# SWM221 register map
File version: 1.0
CPU: CM0 r1p0, little endian, 2 interrupt priority bits
Registers are 32-bit, read-write, no defined reset value unless marked. A register's access mark holds for its fields unless they carry their own. Offsets are from the block's base; [hi:lo] are bit positions; lines under a group give offsets from that group; {n}, {i} and the like mark numbered series; 'fields as' and 'values as' point back to an identical list.

## I2C0 — Registers group
Base 0x40042000
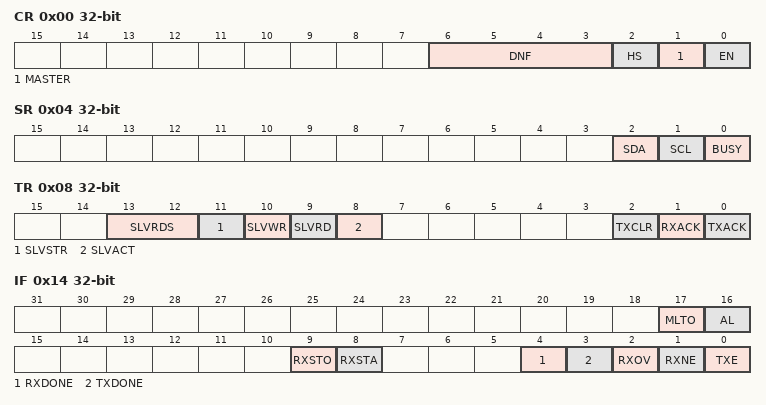
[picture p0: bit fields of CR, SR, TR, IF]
0x00 CR
  [6:3] DNF, [2] HS, [1] MASTER, [0] EN
0x04 SR
  [2] SDA, [1] SCL, [0] BUSY
0x08 TR
  [13:12] SLVRDS, [11] SLVSTR, [10] SLVWR, [9] SLVRD, [8] SLVACT, [2] TXCLR, [1] RXACK, [0] TXACK
0x0C RXDATA
0x10 TXDATA
0x14 IF
  [17] MLTO, [16] AL, [9] RXSTO, [8] RXSTA, [4] RXDONE, [3] TXDONE, [2] RXOV, [1] RXNE, [0] TXE
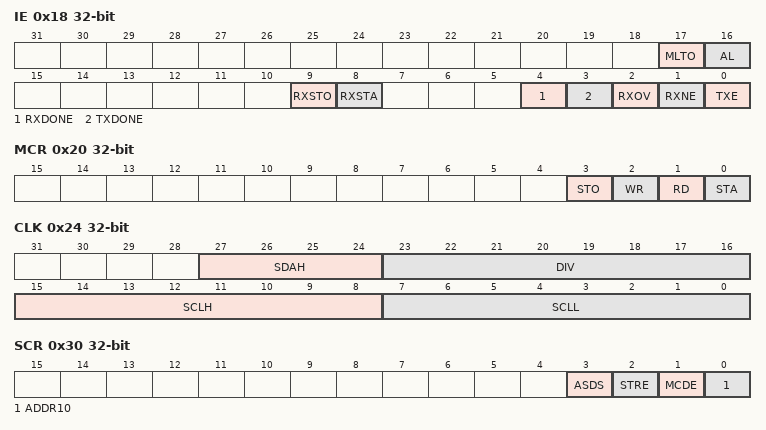
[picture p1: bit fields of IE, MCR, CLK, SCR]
0x18 IE
  fields as IF
0x20 MCR
  [3] STO, [2] WR, [1] RD, [0] STA
0x24 CLK
  [27:24] SDAH, [23:16] DIV, [15:8] SCLH, [7:0] SCLL
0x30 SCR
  [3] ASDS, [2] STRE, [1] MCDE, [0] ADDR10
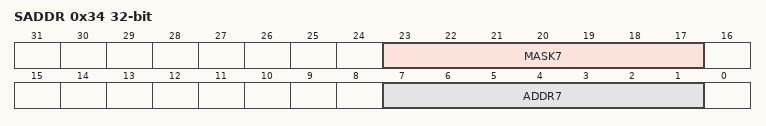
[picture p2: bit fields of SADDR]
0x34 SADDR
  [23:17] MASK7, [7:1] ADDR7

## CAN0 — Registers group
Base 0x40042800
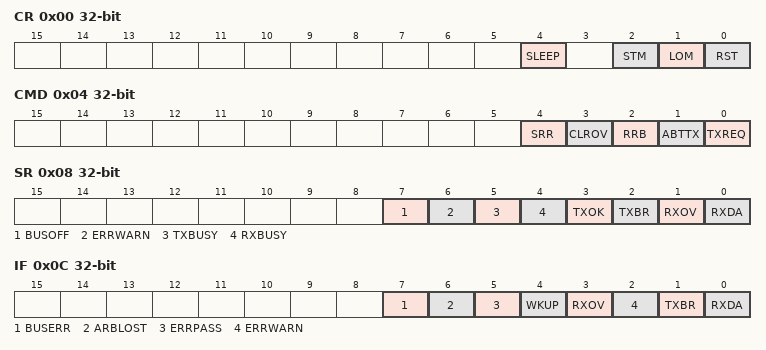
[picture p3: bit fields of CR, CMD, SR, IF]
0x00 CR
  [4] SLEEP, [2] STM, [1] LOM, [0] RST
0x04 CMD wo
  [4] SRR, [3] CLROV, [2] RRB, [1] ABTTX, [0] TXREQ
0x08 SR ro
  [7] BUSOFF, [6] ERRWARN, [5] TXBUSY, [4] RXBUSY, [3] TXOK, [2] TXBR, [1] RXOV, [0] RXDA
0x0C IF
  [7] BUSERR, [6] ARBLOST, [5] ERRPASS, [4] WKUP, [3] RXOV, [2] ERRWARN, [1] TXBR, [0] RXDA
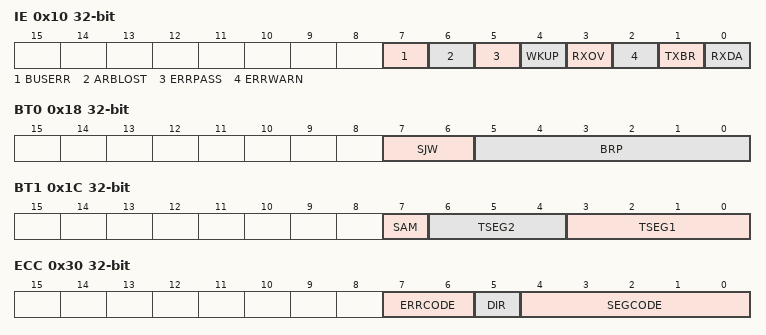
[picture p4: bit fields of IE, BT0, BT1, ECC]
0x10 IE
  fields as IF
0x14 BT2
  [3:0] BRP
0x18 BT0
  [7:6] SJW, [5:0] BRP
0x1C BT1
  [7] SAM, [6:4] TSEG2, [3:0] TSEG1
0x24 AFM
0x28 AFE
0x2C ALC ro
0x30 ECC ro
  [7:6] ERRCODE, [5] DIR, [4:0] SEGCODE
0x34 EWLIM
0x38 RXERR
0x3C TXERR
0x40 FRAME group — register cluster
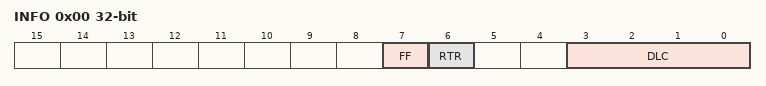
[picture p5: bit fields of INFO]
  0x00 INFO
    [7] FF, [6] RTR, [3:0] DLC
  {0x4+4j} DATA[{j}] (j=0..11)
0x74 RMCNT ro
{0x300+4i} ACR[{i}] (i=0..15)
{0x380+4i} AMR[{i}] (i=0..15)

## ADC0 — Registers group
Base 0x40044800
Same registers: ADC1 0x40044900
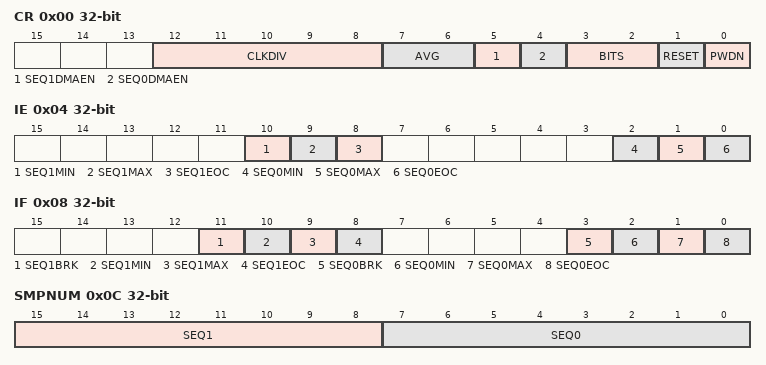
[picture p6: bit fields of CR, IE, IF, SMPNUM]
0x00 CR
  [12:8] CLKDIV, [7:6] AVG, [5] SEQ1DMAEN, [4] SEQ0DMAEN, [3:2] BITS, [1] RESET, [0] PWDN
0x04 IE
  [10] SEQ1MIN, [9] SEQ1MAX, [8] SEQ1EOC, [2] SEQ0MIN, [1] SEQ0MAX, [0] SEQ0EOC
0x08 IF
  [11] SEQ1BRK, [10] SEQ1MIN, [9] SEQ1MAX, [8] SEQ1EOC, [3] SEQ0BRK, [2] SEQ0MIN, [1] SEQ0MAX, [0] SEQ0EOC
0x0C SMPNUM
  [15:8] SEQ1, [7:0] SEQ0
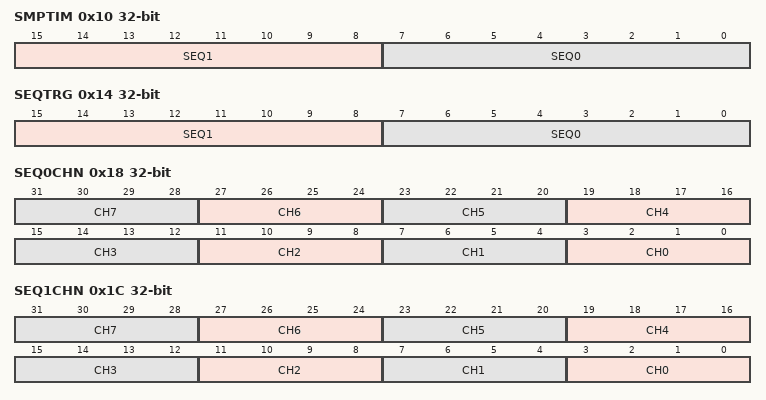
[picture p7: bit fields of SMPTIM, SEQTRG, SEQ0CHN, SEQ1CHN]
0x10 SMPTIM
  [15:8] SEQ1, [7:0] SEQ0
0x14 SEQTRG
  [15:8] SEQ1, [7:0] SEQ0
0x18 SEQ0CHN
  [4n+3:4n] CH{n} (n=0..7)
0x1C SEQ1CHN
  [4n+3:4n] CH{n} (n=0..7)
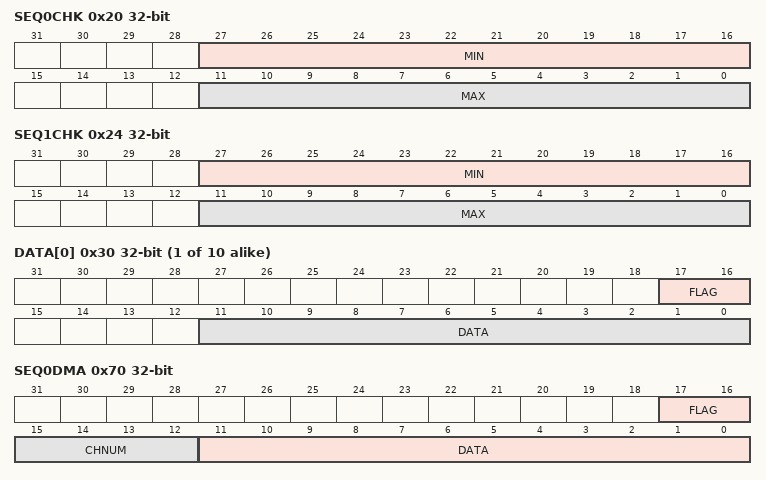
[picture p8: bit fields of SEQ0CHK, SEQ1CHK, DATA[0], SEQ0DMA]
0x20 SEQ0CHK
  [27:16] MIN, [11:0] MAX
0x24 SEQ1CHK
  [27:16] MIN, [11:0] MAX
{0x30+4i} DATA[{i}] (i=0..9)
  [17:16] FLAG, [11:0] DATA
0x70 SEQ0DMA
  [17:16] FLAG, [15:12] CHNUM, [11:0] DATA
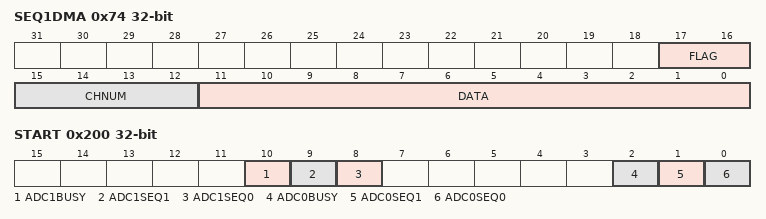
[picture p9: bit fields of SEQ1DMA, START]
0x74 SEQ1DMA
  [17:16] FLAG, [15:12] CHNUM, [11:0] DATA
0x200 START
  [10] ADC1BUSY, [9] ADC1SEQ1, [8] ADC1SEQ0, [2] ADC0BUSY, [1] ADC0SEQ1, [0] ADC0SEQ0

## PWM0 — Registers group
Base 0x40043000
Same registers: PWM1 0x40043080
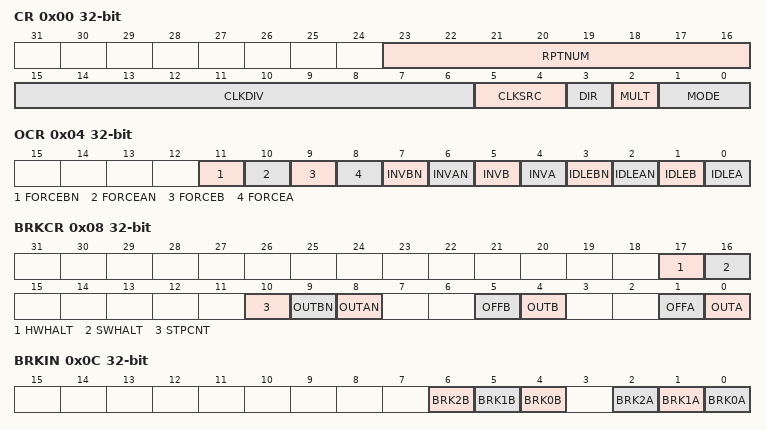
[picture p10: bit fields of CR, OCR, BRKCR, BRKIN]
0x00 CR
  [23:16] RPTNUM, [15:6] CLKDIV, [5:4] CLKSRC, [3] DIR, [2] MULT, [1:0] MODE
0x04 OCR
  [11] FORCEBN, [10] FORCEAN, [9] FORCEB, [8] FORCEA, [7] INVBN, [6] INVAN, [5] INVB, [4] INVA, [3] IDLEBN, [2] IDLEAN, [1] IDLEB, [0] IDLEA
0x08 BRKCR
  [17] HWHALT, [16] SWHALT, [10] STPCNT, [9] OUTBN, [8] OUTAN, [5] OFFB, [4] OUTB, [1] OFFA, [0] OUTA
0x0C BRKIN
  [6] BRK2B, [5] BRK1B, [4] BRK0B, [2] BRK2A, [1] BRK1A, [0] BRK0A
0x20 PERIOD
0x24 CMPA
0x28 CMPB
0x2C DZA
0x30 DZB
0x34 CMPA2
0x38 CMPB2
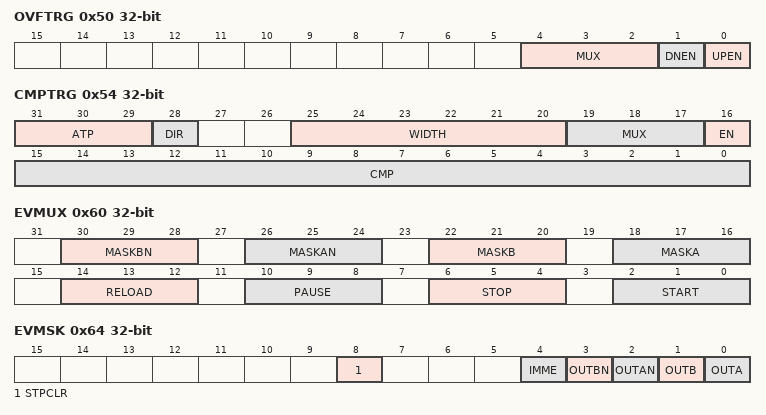
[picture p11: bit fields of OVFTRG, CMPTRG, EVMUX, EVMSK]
0x50 OVFTRG
  [4:2] MUX, [1] DNEN, [0] UPEN
0x54 CMPTRG
  [31:29] ATP, [28] DIR, [25:20] WIDTH, [19:17] MUX, [16] EN, [15:0] CMP
0x58 CMPTRG2
  [2:0] INTV
0x60 EVMUX
  [30:28] MASKBN, [26:24] MASKAN, [22:20] MASKB, [18:16] MASKA, [14:12] RELOAD, [10:8] PAUSE, [6:4] STOP, [2:0] START
0x64 EVMSK
  [8] STPCLR, [4] IMME, [3] OUTBN, [2] OUTAN, [1] OUTB, [0] OUTA
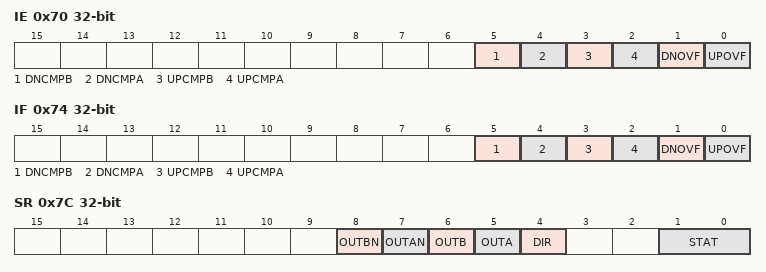
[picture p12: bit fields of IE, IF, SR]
0x70 IE
  [5] DNCMPB, [4] DNCMPA, [3] UPCMPB, [2] UPCMPA, [1] DNOVF, [0] UPOVF
0x74 IF
  [5] DNCMPB, [4] DNCMPA, [3] UPCMPB, [2] UPCMPA, [1] DNOVF, [0] UPOVF
0x78 VALUE
0x7C SR
  [8] OUTBN, [7] OUTAN, [6] OUTB, [5] OUTA, [4] DIR, [1:0] STAT

## PWMG — Registers group
Base 0x40043400
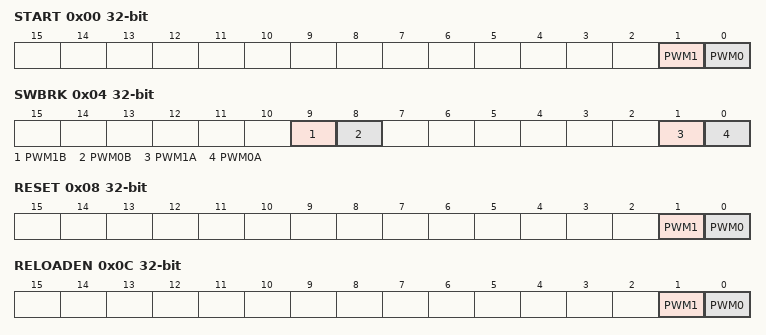
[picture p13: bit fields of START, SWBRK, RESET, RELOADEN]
0x00 START
  [1] PWM1, [0] PWM0
0x04 SWBRK
  [9] PWM1B, [8] PWM0B, [1] PWM1A, [0] PWM0A
0x08 RESET
  [1] PWM1, [0] PWM0
0x0C RELOADEN
  [1] PWM1, [0] PWM0
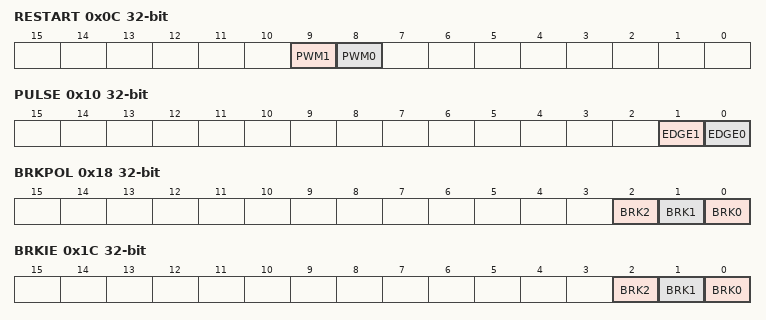
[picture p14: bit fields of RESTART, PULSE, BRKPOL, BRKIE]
0x0C RESTART (alternate view of RELOADEN)
  [9] PWM1, [8] PWM0
0x10 PULSE
  [1] EDGE1, [0] EDGE0
0x14 FILTER
0x18 BRKPOL
  [2] BRK2, [1] BRK1, [0] BRK0
0x1C BRKIE
  [2] BRK2, [1] BRK1, [0] BRK0
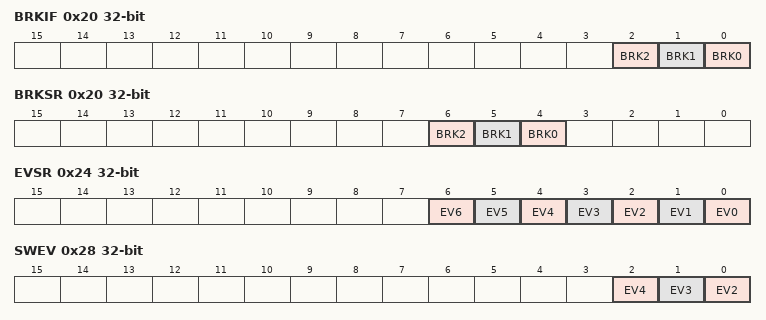
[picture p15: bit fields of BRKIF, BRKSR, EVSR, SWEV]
0x20 BRKIF
  [2] BRK2, [1] BRK1, [0] BRK0
0x20 BRKSR (alternate view of BRKIF)
  [6] BRK2, [5] BRK1, [4] BRK0
0x24 EVSR
  [n] EV{n} (n=0..6)
0x28 SWEV
  [2] EV4, [1] EV3, [0] EV2

## DIV — Registers group
Base 0x40003000
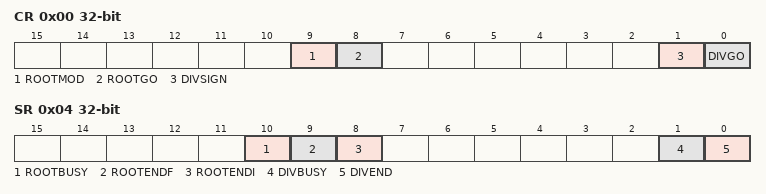
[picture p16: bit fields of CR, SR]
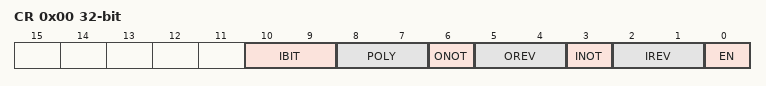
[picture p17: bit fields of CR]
0x00 CR
  [9] ROOTMOD, [8] ROOTGO, [1] DIVSIGN, [0] DIVGO
0x04 SR
  [10] ROOTBUSY, [9] ROOTENDF, [8] ROOTENDI, [1] DIVBUSY, [0] DIVEND
0x08 IE
0x10 DIVIDEND
0x14 DIVISOR
0x18 QUO
0x1C REMAIN
0x20 RADICAND
0x24 ROOT

## CRC — Registers group
Base 0x40002800
0x00 CR
  [10:9] IBIT, [8:7] POLY, [6] ONOT, [5:4] OREV, [3] INOT, [2:1] IREV, [0] EN
0x04 DATAIN wo
0x08 INIVAL
0x0C RESULT ro

## DMA — Registers group
Base 0x40000800
0x00 IF
  [7] ERR1, [6] HALF1, [5] DONE1, [4] GLB1, [3] ERR0, [2] HALF0, [1] DONE0, [0] GLB0
0x04 IFC
  fields as IF
0x10 CH0 group — register cluster
  0x00 MUX
    [11] EXTHSEN, [10:8] EXTHSSIG, [7] MWRHSEN, [5:4] MWRHSSIG, [3] MRDHSEN, [1:0] MRDHSSIG
  0x04 CR
    [16] MEM2MEM, [15:12] PL, [11:10] MSIZ, [9:8] PSIZ, [7] MINC, [6] PINC, [5] CIRC, [4] DIR, [3] ERRIE, [2] HALFIE, [1] DONEIE, [0] EN
  0x08 NDT
    [31:16] HALF, [15:0] LEN
  0x0C PAR
  0x10 MAR
0x30 CH1 group — register cluster
  0x00 MUX
    fields as CH0.MUX
  0x04 CR
    fields as CH0.CR
  0x08 NDT
    [31:16] HALF, [15:0] LEN
  0x0C PAR
  0x10 MAR

## MPU — Registers group
Base 0x40005000
0x08 SR
  [2] ENDIAN, [1] DMAEN, [0] BUSY
0x0C CR
  [21:20] CS0WR0, [19:16] WRHOLD, [15:14] WR1CS1, [13:10] WCS1_0, [9:5] RDHOLD, [4:0] RCS1_0

## FMC — Registers group
Base 0x40045000
0x00 DATA
0x04 ADDR
0x08 ERASE
  [31:24] REQ, [16:0] ADDR
0x0C CACHE
  [31] CCLR, [1] CPEN, [0] CEN
0x10 CFG0
  [9] WREN
{0x10+4i} CFG{i} (i=1..4)
0x24 STAT
  [31] IDLE, [30] INITDONE, [7] READONLY, [4] FIFOFULL, [3] FIFOEMPTY, [2] READBUSY, [1] PROGBUSY, [0] ERASEBUSY
0x28 REMAP
  [6:1] OFFSET, [0] ON

## WDT — Registers group
Base 0x40046800
0x00 RSTVAL
0x04 INTVAL
0x08 CR
  [11:8] CLKDIV, [3] WINEN, [2] INTEN, [1] RSTEN, [0] EN
0x0C IF
0x10 FEED

## QEI — Registers group
Base 0x40041000
0x00 CR
  [10] PAUSE, [9] INDEX, [7] MODE, [6] RSTSRC, [5] X2X4, [4] ABSWAP, [0] ENA
0x04 POSCNT
0x08 MAXCNT
0x20 IE
  [3] ERROR, [2] CNTOV, [1] MATCH, [0] INDEX
0x24 IM
  [3] ERROR, [2] CNTOV, [1] MATCH, [0] INDEX
0x28 IC wo
  [3] ERROR, [2] CNTOV, [1] MATCH, [0] INDEX
0x2C IF ro
  [3] ERROR, [2] CNTOV, [1] MATCH, [0] INDEX
0x30 IFOV
  [3] ERROR, [2] CNTOV, [1] MATCH, [0] INDEX
